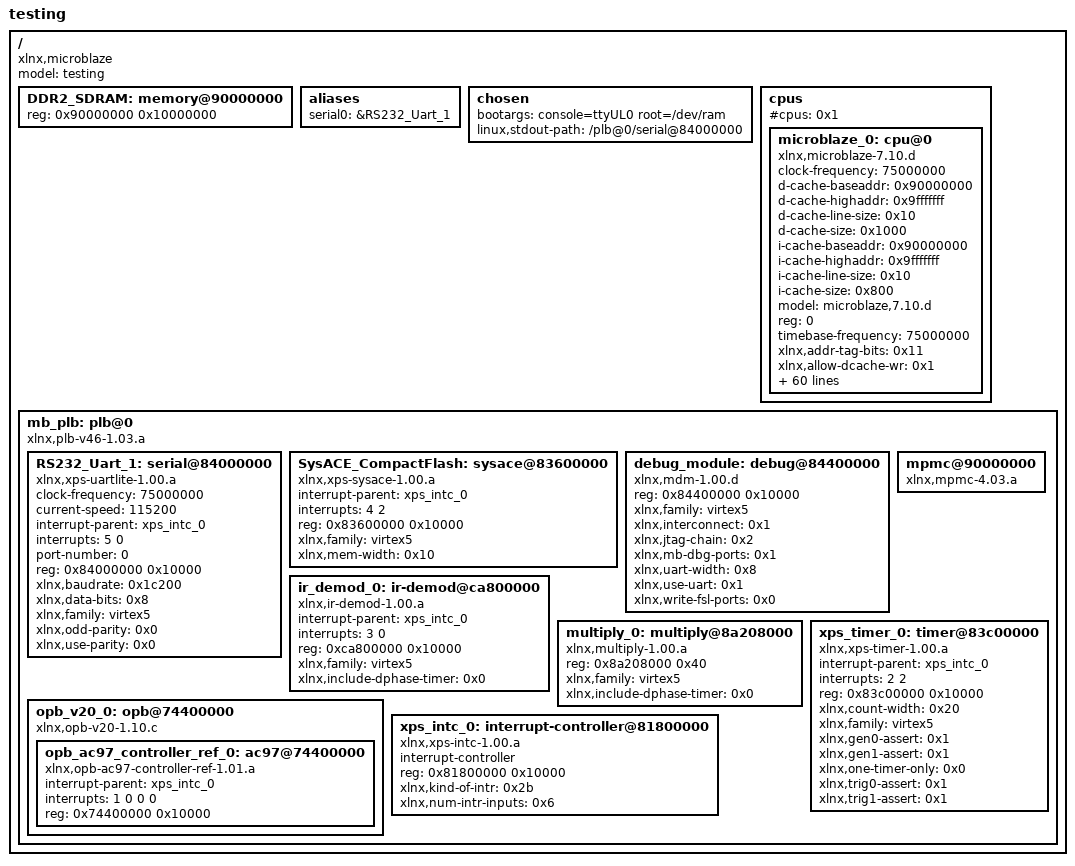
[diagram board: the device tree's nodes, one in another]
/*
 * Device Tree Generator version: 1.3
 *
 * (C) Copyright 2007-2008 Xilinx, Inc.
 * (C) Copyright 2007-2009 Michal Simek
 *
 * Michal SIMEK <monstr@monstr.eu>
 *
 * This program is free software; you can redistribute it and/or
 * modify it under the terms of the GNU General Public License as
 * published by the Free Software Foundation; either version 2 of
 * the License, or (at your option) any later version.
 *
 * This program is distributed in the hope that it will be useful,
 * but WITHOUT ANY WARRANTY; without even the implied warranty of
 * MERCHANTABILITY or FITNESS FOR A PARTICULAR PURPOSE. See the
 * GNU General Public License for more details.
 *
 * You should have received a copy of the GNU General Public License
 * along with this program; if not, write to the Free Software
 * Foundation, Inc., 59 Temple Place, Suite 330, Boston,
 * MA 02111-1307 USA
 *
 * CAUTION: This file is automatically generated by libgen.
 * Version: Xilinx EDK 10.1.03 EDK_K_SP3.6
 *
 * XPS project directory: lab8
 */

/dts-v1/;
/ {
	#address-cells = <1>;
	#size-cells = <1>;
	compatible = "xlnx,microblaze";
	model = "testing";
	DDR2_SDRAM: memory@90000000 {
		device_type = "memory";
		reg = < 0x90000000 0x10000000 >;
	} ;
	aliases {
		serial0 = &RS232_Uart_1;
	} ;
	chosen {
		bootargs = "console=ttyUL0 root=/dev/ram";
		linux,stdout-path = "/plb@0/serial@84000000";
	} ;
	cpus {
		#address-cells = <1>;
		#cpus = <0x1>;
		#size-cells = <0>;
		microblaze_0: cpu@0 {
			clock-frequency = <75000000>;
			compatible = "xlnx,microblaze-7.10.d";
			d-cache-baseaddr = <0x90000000>;
			d-cache-highaddr = <0x9fffffff>;
			d-cache-line-size = <0x10>;
			d-cache-size = <0x1000>;
			device_type = "cpu";
			i-cache-baseaddr = <0x90000000>;
			i-cache-highaddr = <0x9fffffff>;
			i-cache-line-size = <0x10>;
			i-cache-size = <0x800>;
			model = "microblaze,7.10.d";
			reg = <0>;
			timebase-frequency = <75000000>;
			xlnx,addr-tag-bits = <0x11>;
			xlnx,allow-dcache-wr = <0x1>;
			xlnx,allow-icache-wr = <0x1>;
			xlnx,area-optimized = <0x0>;
			xlnx,cache-byte-size = <0x800>;
			xlnx,d-lmb = <0x1>;
			xlnx,d-opb = <0x0>;
			xlnx,d-plb = <0x1>;
			xlnx,data-size = <0x20>;
			xlnx,dcache-addr-tag = <0x10>;
			xlnx,dcache-always-used = <0x0>;
			xlnx,dcache-byte-size = <0x1000>;
			xlnx,dcache-line-len = <0x4>;
			xlnx,dcache-use-fsl = <0x1>;
			xlnx,debug-enabled = <0x1>;
			xlnx,div-zero-exception = <0x0>;
			xlnx,dopb-bus-exception = <0x0>;
			xlnx,dynamic-bus-sizing = <0x1>;
			xlnx,edge-is-positive = <0x1>;
			xlnx,family = "virtex5";
			xlnx,fpu-exception = <0x0>;
			xlnx,fsl-data-size = <0x20>;
			xlnx,fsl-exception = <0x0>;
			xlnx,fsl-links = <0x0>;
			xlnx,i-lmb = <0x1>;
			xlnx,i-opb = <0x0>;
			xlnx,i-plb = <0x1>;
			xlnx,icache-always-used = <0x0>;
			xlnx,icache-line-len = <0x4>;
			xlnx,icache-use-fsl = <0x1>;
			xlnx,ill-opcode-exception = <0x0>;
			xlnx,instance = "microblaze_0";
			xlnx,interconnect = <0x1>;
			xlnx,interrupt-is-edge = <0x0>;
			xlnx,iopb-bus-exception = <0x0>;
			xlnx,mmu-dtlb-size = <0x4>;
			xlnx,mmu-itlb-size = <0x2>;
			xlnx,mmu-tlb-access = <0x3>;
			xlnx,mmu-zones = <0x2>;
			xlnx,number-of-pc-brk = <0x1>;
			xlnx,number-of-rd-addr-brk = <0x0>;
			xlnx,number-of-wr-addr-brk = <0x0>;
			xlnx,opcode-0x0-illegal = <0x0>;
			xlnx,pvr = <0x0>;
			xlnx,pvr-user1 = <0x0>;
			xlnx,pvr-user2 = <0x0>;
			xlnx,reset-msr = <0x0>;
			xlnx,sco = <0x0>;
			xlnx,unaligned-exceptions = <0x0>;
			xlnx,use-barrel = <0x1>;
			xlnx,use-dcache = <0x1>;
			xlnx,use-div = <0x0>;
			xlnx,use-ext-brk = <0x1>;
			xlnx,use-ext-nm-brk = <0x1>;
			xlnx,use-extended-fsl-instr = <0x0>;
			xlnx,use-fpu = <0x0>;
			xlnx,use-hw-mul = <0x1>;
			xlnx,use-icache = <0x1>;
			xlnx,use-interrupt = <0x1>;
			xlnx,use-mmu = <0x3>;
			xlnx,use-msr-instr = <0x1>;
			xlnx,use-pcmp-instr = <0x1>;
		} ;
	} ;
	mb_plb: plb@0 {
		#address-cells = <1>;
		#size-cells = <1>;
		compatible = "xlnx,plb-v46-1.03.a", "xlnx,plb-v46-1.00.a", "simple-bus";
		ranges ;
		RS232_Uart_1: serial@84000000 {
			clock-frequency = <75000000>;
			compatible = "xlnx,xps-uartlite-1.00.a";
			current-speed = <115200>;
			device_type = "serial";
			interrupt-parent = <&xps_intc_0>;
			interrupts = < 5 0 >;
			port-number = <0>;
			reg = < 0x84000000 0x10000 >;
			xlnx,baudrate = <0x1c200>;
			xlnx,data-bits = <0x8>;
			xlnx,family = "virtex5";
			xlnx,odd-parity = <0x0>;
			xlnx,use-parity = <0x0>;
		} ;
		SysACE_CompactFlash: sysace@83600000 {
			compatible = "xlnx,xps-sysace-1.00.a";
			interrupt-parent = <&xps_intc_0>;
			interrupts = < 4 2 >;
			reg = < 0x83600000 0x10000 >;
			xlnx,family = "virtex5";
			xlnx,mem-width = <0x10>;
		} ;
		debug_module: debug@84400000 {
			compatible = "xlnx,mdm-1.00.d";
			reg = < 0x84400000 0x10000 >;
			xlnx,family = "virtex5";
			xlnx,interconnect = <0x1>;
			xlnx,jtag-chain = <0x2>;
			xlnx,mb-dbg-ports = <0x1>;
			xlnx,uart-width = <0x8>;
			xlnx,use-uart = <0x1>;
			xlnx,write-fsl-ports = <0x0>;
		} ;
		ir_demod_0: ir-demod@ca800000 {
			compatible = "xlnx,ir-demod-1.00.a";
			interrupt-parent = <&xps_intc_0>;
			interrupts = < 3 0 >;
			reg = < 0xca800000 0x10000 >;
			xlnx,family = "virtex5";
			xlnx,include-dphase-timer = <0x0>;
		} ;
		mpmc@90000000 {
			#address-cells = <1>;
			#size-cells = <1>;
			compatible = "xlnx,mpmc-4.03.a";
		} ;
		multiply_0: multiply@8a208000 {
			compatible = "xlnx,multiply-1.00.a";
			reg = < 0x8a208000 0x40 >;
			xlnx,family = "virtex5";
			xlnx,include-dphase-timer = <0x0>;
		} ;
		opb_v20_0: opb@74400000 {
			#address-cells = <1>;
			#size-cells = <1>;
			compatible = "xlnx,opb-v20-1.10.c", "simple-bus";
			ranges = < 0x74400000 0x74400000 0x10000 >;
			opb_ac97_controller_ref_0: ac97@74400000 {
				compatible = "xlnx,opb-ac97-controller-ref-1.01.a";
				interrupt-parent = <&xps_intc_0>;
				interrupts = < 1 0 0 0 >;
				reg = < 0x74400000 0x10000 >;
			} ;
		} ;
		xps_intc_0: interrupt-controller@81800000 {
			#interrupt-cells = <0x2>;
			compatible = "xlnx,xps-intc-1.00.a";
			interrupt-controller ;
			reg = < 0x81800000 0x10000 >;
			xlnx,kind-of-intr = <0x2b>;
			xlnx,num-intr-inputs = <0x6>;
		} ;
		xps_timer_0: timer@83c00000 {
			compatible = "xlnx,xps-timer-1.00.a";
			interrupt-parent = <&xps_intc_0>;
			interrupts = < 2 2 >;
			reg = < 0x83c00000 0x10000 >;
			xlnx,count-width = <0x20>;
			xlnx,family = "virtex5";
			xlnx,gen0-assert = <0x1>;
			xlnx,gen1-assert = <0x1>;
			xlnx,one-timer-only = <0x0>;
			xlnx,trig0-assert = <0x1>;
			xlnx,trig1-assert = <0x1>;
		} ;
	} ;
}  ;
